# EFR32BG29B230F1024CM40 register map
Vendor: Silicon Labs; Series: EFR32; File version: C
Registers are 32-bit, read-write, reset 0x0 unless marked. A register's access mark holds for its fields unless they carry their own. Offsets are from the block's base; [hi:lo] are bit positions; {n}, {i} and the like mark numbered series.

## SEMAILBOX_NS_HOST — SEMAILBOX_NS_HOST Registers
Base 0x5C000000
Same registers: SEMAILBOX_S_HOST 0x4C000000
0x00 FIFO — A write access to any address in this area will be mapped to the TX FIFO (only for the payload). A read access to any address in this area will be mapped to the RX FIFO (only for the payload). Using an address range (16 x 32-bit) rather than one single address mapped to the FIFO allows using incremental bursts.
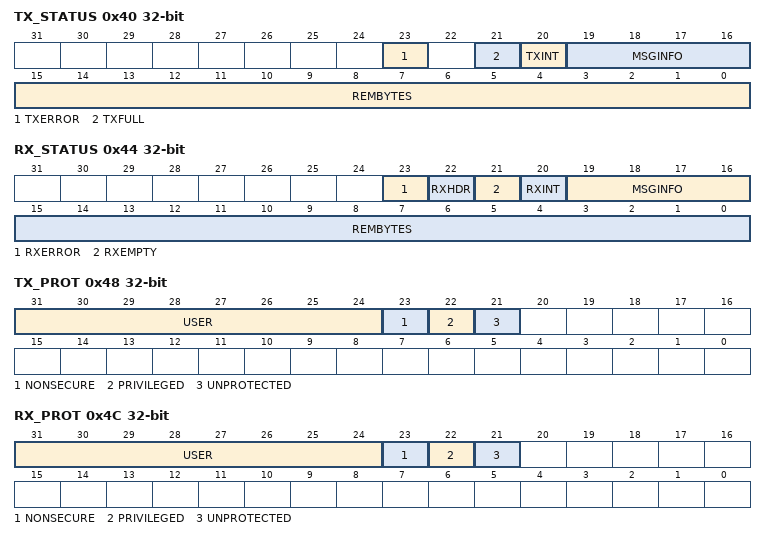
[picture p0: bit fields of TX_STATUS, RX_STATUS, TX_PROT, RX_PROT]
0x40 TX_STATUS ro
  [23] TXERROR, [21] TXFULL, [20] TXINT, [19:16] MSGINFO, [15:0] REMBYTES
0x44 RX_STATUS ro
  [23] RXERROR, [22] RXHDR, [21] RXEMPTY, [20] RXINT, [19:16] MSGINFO, [15:0] REMBYTES
0x48 TX_PROT ro — TX Protection register.
  [31:24] USER, [23] NONSECURE, [22] PRIVILEGED, [21] UNPROTECTED
0x4C RX_PROT ro — RX Protection register.
  [31:24] USER, [23] NONSECURE, [22] PRIVILEGED, [21] UNPROTECTED
0x50 TX_HEADER wo — A write access to this register will be mapped to the TX FIFO (only for header).
  [31:0] TXHEADER
0x54 RX_HEADER ro — A read access to this register will be mapped to the RX FIFO (only for the header).
  [31:0] RXHEADER
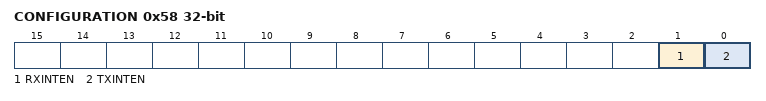
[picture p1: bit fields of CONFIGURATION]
0x58 CONFIGURATION
  [1] RXINTEN, [0] TXINTEN

## SMU_NS_CFGNS — SMU_NS_CFGNS Registers
Base 0x5400C000
Same registers: SMU_S_CFGNS 0x4400C000
0x04 NSSTATUS ro
  [0] SMUNSLOCK — SMUNS Lock Status
    0=UNLOCKED (SMUNSLOCK is Unlocked); 1=LOCKED (SMUNSLOCK is Locked)
0x08 NSLOCK wo
  [23:0] SMUNSLOCKKEY — SMU Non-Secure Lock/Key
    0xACCE55=UNLOCK (Unlocks Registers)
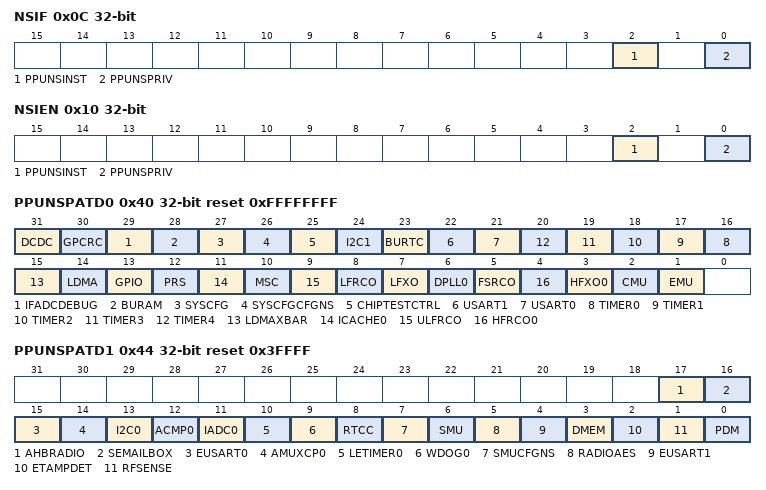
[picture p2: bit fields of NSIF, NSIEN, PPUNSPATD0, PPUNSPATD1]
0x0C NSIF
  [2] PPUNSINST — PPUNS Instruction Interrupt Flag
  [0] PPUNSPRIV — PPUNS Privilege Interrupt Flag
0x10 NSIEN
  [2] PPUNSINST — PPUNS Instruction Interrupt Enable
  [0] PPUNSPRIV — PPUNS Privilege Interrupt Enable
0x40 PPUNSPATD0 reset 0xFFFFFFFF — Set peripheral bits to 1 to mark as privileged access only
  [31] DCDC — DCDC Privileged Access
  [30] GPCRC — GPCRC Privileged Access
  [29] IFADCDEBUG — IFADCDEBUG Privileged Access
  [28] BURAM — BURAM Privileged Access
  [27] SYSCFG — SYSCFG Privileged Access
  [26] SYSCFGCFGNS — SYSCFGCFGNS Privileged Access
  [25] CHIPTESTCTRL — CHIPTESTCTRL Privileged Access
  [24] I2C1 — I2C1 Privileged Access
  [23] BURTC — BURTC Privileged Access
  [22] USART1 — USART1 Privileged Access
  [21] USART0 — USART0 Privileged Access
  [n+16] TIMER{n} (n=0..4) — TIMER{n} Privileged Access
  [15] LDMAXBAR — LDMAXBAR Privileged Access
  [14] LDMA — LDMA Privileged Access
  [13] GPIO — GPIO Privileged Access
  [12] PRS — PRS Privileged Access
  [11] ICACHE0 — ICACHE0 Privileged Access
  [10] MSC — MSC Privileged Access
  [9] ULFRCO — ULFRCO Privileged Access
  [8] LFRCO — LFRCO Privileged Access
  [7] LFXO — LFXO Privileged Access
  [6] DPLL0 — DPLL0 Privileged Access
  [5] FSRCO — FSRCO Privileged Access
  [4] HFRCO0 — HFRCO0 Privileged Access
  [3] HFXO0 — HFXO0 Privileged Access
  [2] CMU — CMU Privileged Access
  [1] EMU — EMU Privileged Access
0x44 PPUNSPATD1 reset 0x3FFFF — Set peripheral bits to 1 to mark as privileged access only
  [17] AHBRADIO — AHBRADIO Privileged Access
  [16] SEMAILBOX — SEMAILBOX Privileged Access
  [15] EUSART0 — EUSART0 Privileged Access
  [14] AMUXCP0 — AMUXCP0 Privileged Access
  [13] I2C0 — I2C0 Privileged Access
  [12] ACMP0 — ACMP0 Privileged Access
  [11] IADC0 — IADC0 Privileged Access
  [10] LETIMER0 — LETIMER0 Privileged Access
  [9] WDOG0 — WDOG0 Privileged Access
  [8] RTCC — RTCC Privileged Access
  [7] SMUCFGNS — SMUCFGNS Privileged Access
  [6] SMU — SMU Privileged Access
  [5] RADIOAES — RADIOAES Privileged Access
  [4] EUSART1 — EUSART1 Privileged Access
  [3] DMEM — DMEM Privileged Access
  [2] ETAMPDET — ETAMPDET Privileged Access
  [1] RFSENSE — RFSENSE Privileged Access
  [0] PDM — PDM Privileged Access
0x140 PPUNSFS ro
  [7:0] PPUFSPERIPHID — Peripheral I
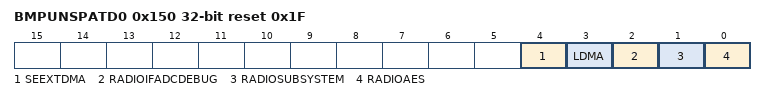
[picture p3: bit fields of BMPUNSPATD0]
0x150 BMPUNSPATD0 reset 0x1F
  [4] SEEXTDMA — SEEXTDMA Privileged Mode
  [3] LDMA — LDMA Privileged Mode
  [2] RADIOIFADCDEBUG — RADIOIFADCDEBUG Privileged Mode
  [1] RADIOSUBSYSTEM — RADIOSUBSYSTEM Privileged Mode
  [0] RADIOAES — RADIOAES Privileged Mode
